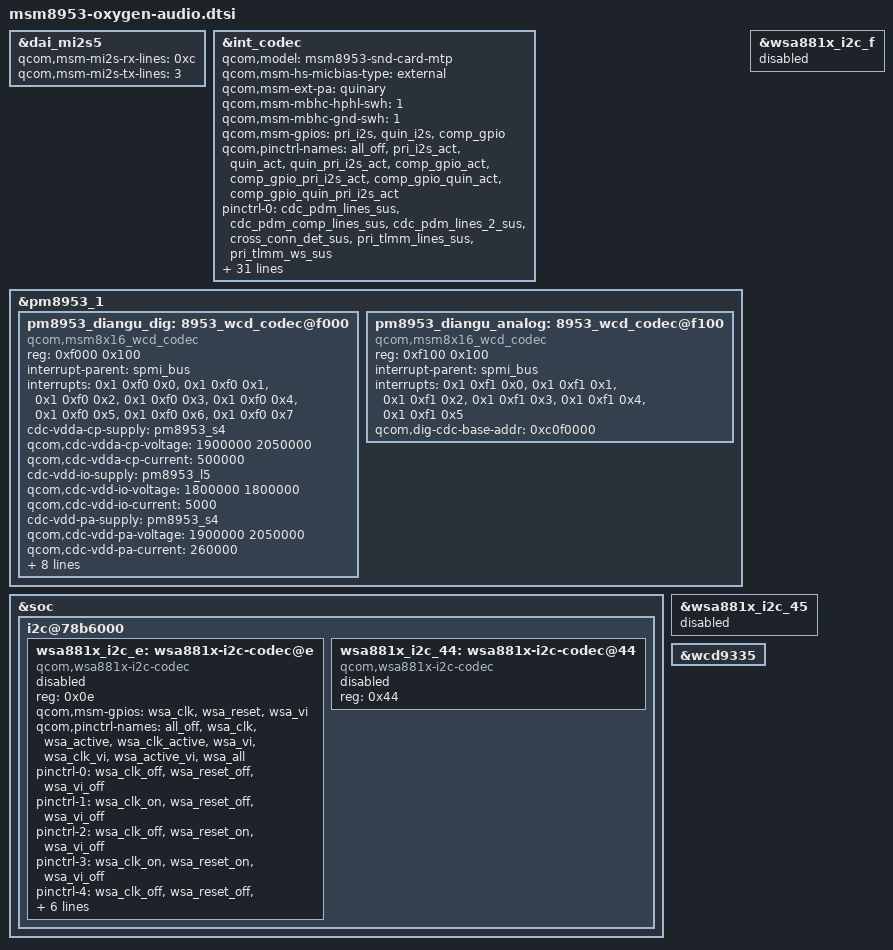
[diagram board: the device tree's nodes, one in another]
/*
 * Copyright (c) 2015-2018, The Linux Foundation. All rights reserved.
 *
 * This program is free software; you can redistribute it and/or modify
 * it under the terms of the GNU General Public License version 2 and
 * only version 2 as published by the Free Software Foundation.
 *
 * This program is distributed in the hope that it will be useful,
 * but WITHOUT ANY WARRANTY; without even the implied warranty of
 * MERCHANTABILITY or FITNESS FOR A PARTICULAR PURPOSE.  See the
 * GNU General Public License for more details.
 */

&dai_mi2s5 {
	qcom,msm-mi2s-rx-lines = <0xc>;
	qcom,msm-mi2s-tx-lines = <3>;
};

&int_codec {
	status = "okay";
	qcom,model = "msm8953-snd-card-mtp";
	qcom,msm-hs-micbias-type = "external";
	qcom,msm-ext-pa = "quinary";
	/delete-property/ qcom,hdmi-dba-codec-rx;
	/delete-property/ qcom,cdc-us-euro-gpios;

	qcom,msm-mbhc-hphl-swh = <1>;
	qcom,msm-mbhc-gnd-swh = <1>;

	qcom,msm-gpios =
		"pri_i2s",
		"quin_i2s",
		"comp_gpio";
	qcom,pinctrl-names =
		"all_off",
		"pri_i2s_act",
		"quin_act",
		"quin_pri_i2s_act",
		"comp_gpio_act",
		"comp_gpio_pri_i2s_act",
		"comp_gpio_quin_act",
		"comp_gpio_quin_pri_i2s_act";

	pinctrl-names =
		"all_off",
		"pri_i2s_act",
		"quin_act",
		"quin_pri_i2s_act",
		"comp_gpio_act",
		"comp_gpio_pri_i2s_act",
		"comp_gpio_quin_act",
		"comp_gpio_quin_pri_i2s_act";

	pinctrl-0 = <&cdc_pdm_lines_sus &cdc_pdm_comp_lines_sus
		&cdc_pdm_lines_2_sus &cross_conn_det_sus
		&pri_tlmm_lines_sus &pri_tlmm_ws_sus>;
	pinctrl-1 = <&cdc_pdm_lines_act &cdc_pdm_comp_lines_sus
		&cdc_pdm_lines_2_act &cross_conn_det_sus
		&pri_tlmm_lines_sus &pri_tlmm_ws_sus>;
	pinctrl-2 = <&cdc_pdm_lines_sus &cdc_pdm_comp_lines_sus
		&cdc_pdm_lines_2_sus &cross_conn_det_sus
		&pri_tlmm_lines_act &pri_tlmm_ws_act>;
	pinctrl-3 = <&cdc_pdm_lines_act &cdc_pdm_comp_lines_sus
		&cdc_pdm_lines_2_act &cross_conn_det_sus
		&pri_tlmm_lines_act &pri_tlmm_ws_act>;
	pinctrl-4 = <&cdc_pdm_lines_sus &cdc_pdm_comp_lines_act
		&cdc_pdm_lines_2_sus &cross_conn_det_sus
		&pri_tlmm_lines_sus &pri_tlmm_ws_sus>;
	pinctrl-5 = <&cdc_pdm_lines_act &cdc_pdm_comp_lines_act
		&cdc_pdm_lines_2_act &cross_conn_det_sus
		&pri_tlmm_lines_sus &pri_tlmm_ws_sus>;
	pinctrl-6 = <&cdc_pdm_lines_sus &cdc_pdm_comp_lines_act
		&cdc_pdm_lines_2_sus &cross_conn_det_sus
		&pri_tlmm_lines_act &pri_tlmm_ws_act>;
	pinctrl-7 = <&cdc_pdm_lines_act &cdc_pdm_comp_lines_act
		&cdc_pdm_lines_2_act &cross_conn_det_sus
		&pri_tlmm_lines_act &pri_tlmm_ws_act>;

	asoc-codec = <&stub_codec>, <&pm8953_diangu_dig>;
	asoc-codec-names = "msm-stub-codec.1", "cajon_codec";

	/delete-property/ pinctrl-8;
	/delete-property/ pinctrl-9;
	/delete-property/ pinctrl-10;
	/delete-property/ pinctrl-11;
	/delete-property/ pinctrl-12;
	/delete-property/ pinctrl-13;
	/delete-property/ pinctrl-14;
	/delete-property/ pinctrl-15;

	/delete-property/ asoc-wsa-codec-names;
	/delete-property/ asoc-wsa-codec-prefixes;

	/delete-property/ msm-vdd-wsa-switch-supply;
	/delete-property/ qcom,msm-vdd-wsa-switch-voltage;
	/delete-property/ qcom,msm-vdd-wsa-switch-current;
};

&pm8953_1 {
	pm8953_diangu_dig: 8953_wcd_codec@f000 {
		compatible = "qcom,msm8x16_wcd_codec";
		reg = <0xf000 0x100>;
		interrupt-parent = <&spmi_bus>;
		interrupts = <0x1 0xf0 0x0>,
			     <0x1 0xf0 0x1>,
			     <0x1 0xf0 0x2>,
			     <0x1 0xf0 0x3>,
			     <0x1 0xf0 0x4>,
			     <0x1 0xf0 0x5>,
			     <0x1 0xf0 0x6>,
			     <0x1 0xf0 0x7>;
		interrupt-names = "spk_cnp_int",
				  "spk_clip_int",
				  "spk_ocp_int",
				  "ins_rem_det1",
				  "but_rel_det",
				  "but_press_det",
				  "ins_rem_det",
				  "mbhc_int";

		cdc-vdda-cp-supply = <&pm8953_s4>;
		qcom,cdc-vdda-cp-voltage = <1900000 2050000>;
		qcom,cdc-vdda-cp-current = <500000>;

		cdc-vdd-io-supply = <&pm8953_l5>;
		qcom,cdc-vdd-io-voltage = <1800000 1800000>;
		qcom,cdc-vdd-io-current = <5000>;

		cdc-vdd-pa-supply = <&pm8953_s4>;
		qcom,cdc-vdd-pa-voltage = <1900000 2050000>;
		qcom,cdc-vdd-pa-current = <260000>;

		cdc-vdd-mic-bias-supply = <&pm8953_l13>;
		qcom,cdc-vdd-mic-bias-voltage = <3125000 3125000>;
		qcom,cdc-vdd-mic-bias-current = <5000>;

		qcom,cdc-mclk-clk-rate = <9600000>;

		qcom,cdc-static-supplies =  "cdc-vdd-io",
					   "cdc-vdd-pa",
					   "cdc-vdda-cp";

		qcom,cdc-on-demand-supplies = "cdc-vdd-mic-bias";
		qcom,dig-cdc-base-addr = <0xc0f0000>;
	};

	pm8953_diangu_analog: 8953_wcd_codec@f100 {
		compatible = "qcom,msm8x16_wcd_codec";
		reg = <0xf100 0x100>;
		interrupt-parent = <&spmi_bus>;
		interrupts = <0x1 0xf1 0x0>,
			     <0x1 0xf1 0x1>,
			     <0x1 0xf1 0x2>,
			     <0x1 0xf1 0x3>,
			     <0x1 0xf1 0x4>,
			     <0x1 0xf1 0x5>;
		interrupt-names = "ear_ocp_int",
				  "hphr_ocp_int",
				  "hphl_ocp_det",
				  "ear_cnp_int",
				  "hphr_cnp_int",
				  "hphl_cnp_int";
		qcom,dig-cdc-base-addr = <0xc0f0000>;
	};
};

&soc {
	i2c@78b6000 {
		wsa881x_i2c_e: wsa881x-i2c-codec@e {
			status = "disabled";
			compatible = "qcom,wsa881x-i2c-codec";
			reg = <0x0e>;
			qcom,msm-gpios = "wsa_clk",
					"wsa_reset",
					"wsa_vi";
			qcom,pinctrl-names = "all_off",
					"wsa_clk",
					"wsa_active",
					"wsa_clk_active",
					"wsa_vi",
					"wsa_clk_vi",
					"wsa_active_vi",
					"wsa_all";
			pinctrl-names = "all_off",
					"wsa_clk",
					"wsa_active",
					"wsa_clk_active",
					"wsa_vi",
					"wsa_clk_vi",
					"wsa_active_vi",
					"wsa_all";
			pinctrl-0 = <&wsa_clk_off &wsa_reset_off &wsa_vi_off>;
			pinctrl-1 = <&wsa_clk_on &wsa_reset_off &wsa_vi_off>;
			pinctrl-2 = <&wsa_clk_off &wsa_reset_on &wsa_vi_off>;
			pinctrl-3 = <&wsa_clk_on &wsa_reset_on &wsa_vi_off>;
			pinctrl-4 = <&wsa_clk_off &wsa_reset_off &wsa_vi_on>;
			pinctrl-5 = <&wsa_clk_on &wsa_reset_off &wsa_vi_on>;
			pinctrl-6 = <&wsa_clk_off &wsa_reset_on &wsa_vi_on>;
			pinctrl-7 = <&wsa_clk_on &wsa_reset_on &wsa_vi_on>;
		};
		wsa881x_i2c_44: wsa881x-i2c-codec@44 {
			status = "disabled";

			compatible = "qcom,wsa881x-i2c-codec";
			reg = <0x44>;
		};
	};
};

&pm8953_diangu_dig {
	status = "okay";
};

&pm8953_diangu_analog {
	status = "okay";
};

&wsa881x_i2c_e {
	status = "disabled";
};

&wsa881x_i2c_44 {
	status = "disabled";
};

&wsa881x_i2c_f {
	status = "disabled";
};

&wsa881x_i2c_45 {
	status = "disabled";
};

&wcd9335 {
	/delete-property/ cdc-vdd-buck-supply;
	/delete-property/ cdc-buck-sido-supply;
	/delete-property/ cdc-vdd-tx-h-supply;
	/delete-property/ cdc-vdd-rx-h-supply;
	/delete-property/ cdc-vdd-px-supply;
};
